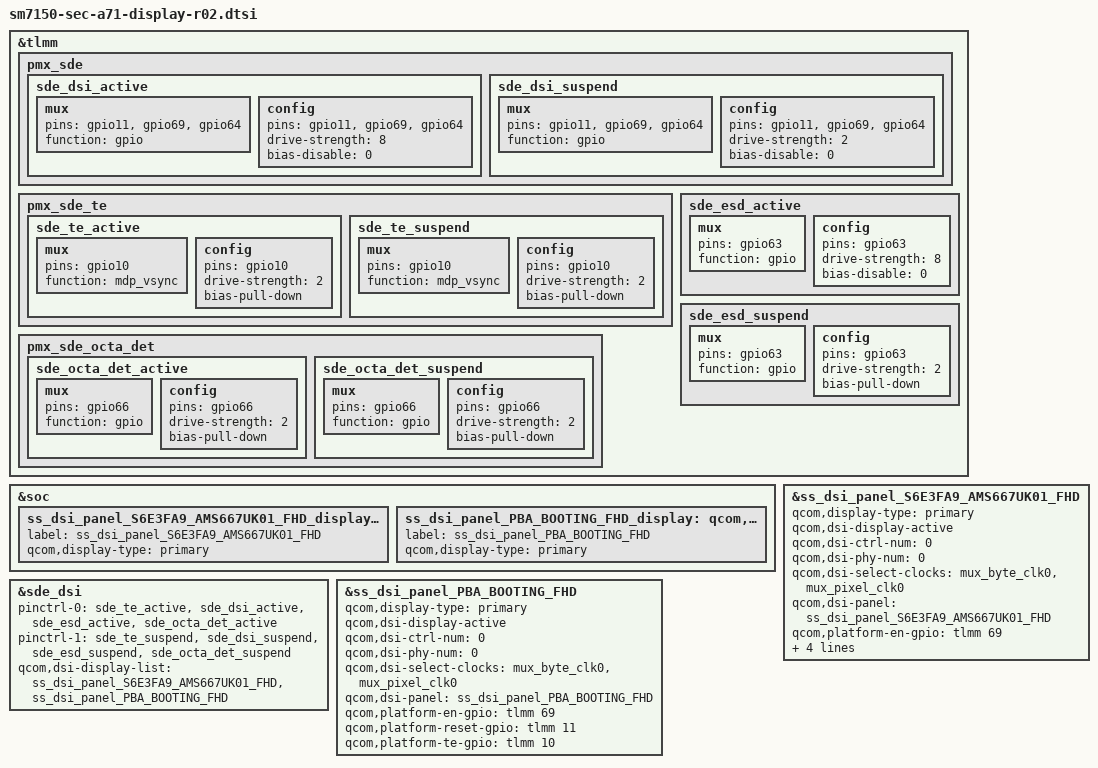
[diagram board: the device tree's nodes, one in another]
/* Copyright (c) 2016-2019, The Linux Foundation. All rights reserved.
 *
 * This program is free software; you can redistribute it and/or modify
 * it under the terms of the GNU General Public License version 2 and
 * only version 2 as published by the Free Software Foundation.
 *
 * This program is distributed in the hope that it will be useful,
 * but WITHOUT ANY WARRANTY; without even the implied warranty of
 * MERCHANTABILITY or FITNESS FOR A PARTICULAR PURPOSE.  See the
 * GNU General Public License for more details.
 */

#include "../../../../../../drivers/gpu/drm/msm/samsung/S6E3FA9_AMS667UK01/dsi_panel_S6E3FA9_AMS667UK01_fhd_octa_cmd.dtsi"
#include "../../../../../../drivers/gpu/drm/msm/samsung/PBA_BOOTING/dsi_panel_PBA_BOOTING_fhd_video.dtsi"

&tlmm {
	pmx_sde: pmx_sde {
		sde_dsi_active: sde_dsi_active {
			mux {
				pins = "gpio11","gpio69", "gpio64";
				function = "gpio";
			};

			config {
				pins = "gpio11","gpio69", "gpio64";
				drive-strength = <8>;   /* 8 mA */
				bias-disable = <0>;   /* no pull */
			};
		};
		sde_dsi_suspend: sde_dsi_suspend {
			mux {
				pins = "gpio11","gpio69", "gpio64";
				function = "gpio";
			};

			config {
				pins = "gpio11","gpio69", "gpio64";
				drive-strength = <2>;   /* 2 mA */
				bias-disable = <0>;   /* no pull */
			};
		};
	};

	pmx_sde_te {
		sde_te_active: sde_te_active {
			mux {
				pins = "gpio10";
				function = "mdp_vsync";
			};

			config {
				pins = "gpio10";
				drive-strength = <2>;   /* 2 mA */
				bias-pull-down;         /* PULL DOWN */
			};
		};

		sde_te_suspend: sde_te_suspend {
			mux {
				pins = "gpio10";
				function = "mdp_vsync";
			};

			config {
				pins = "gpio10";
				drive-strength = <2>;   /* 2 mA */
				bias-pull-down;         /* PULL DOWN */
			};
		};
	};

	pmx_sde_octa_det {
		sde_octa_det_active: sde_octa_det_active {	
			mux {
				pins = "gpio66";
				function = "gpio";
			};

			config {
				pins = "gpio66";
				drive-strength = <2>;   /* 2 mA */
				bias-pull-down;         /* PULL DOWN */
			};
		};

		sde_octa_det_suspend: sde_octa_det_suspend {
			mux {
				pins = "gpio66";
				function = "gpio";
			};

			config {
				pins = "gpio66";
				drive-strength = <2>;   /* 2 mA */
				bias-pull-down;         /* PULL DOWN */
			};
		};
	};
	
		sde_esd_active: sde_esd_active {  /*EL_ON1_DET gpio*/
			mux {
				pins = "gpio63";
				function = "gpio";
			};

			config {
				pins = "gpio63";
				drive-strength = <8>;   /* 8 mA */
				bias-disable = <0>;   /* no pull */
			};
		};
		sde_esd_suspend: sde_esd_suspend {
			mux {
				pins = "gpio63";
				function = "gpio";
			};

			config {
				pins = "gpio63";
				drive-strength = <2>;   /* 2 mA */
				bias-pull-down;         /* PULL DOWN */
			};
		};
};

&soc {
	ss_dsi_panel_S6E3FA9_AMS667UK01_FHD_display: qcom,dsi-display@0 {
		label = "ss_dsi_panel_S6E3FA9_AMS667UK01_FHD";
		qcom,display-type = "primary";
	};

	/* PBA */
	ss_dsi_panel_PBA_BOOTING_FHD_display: qcom,dsi-display@1 {
		label = "ss_dsi_panel_PBA_BOOTING_FHD";
		qcom,display-type = "primary";
	};
};

&sde_dsi {
	pinctrl-names = "panel_active", "panel_suspend";
	pinctrl-0 = <&sde_te_active &sde_dsi_active &sde_esd_active &sde_octa_det_active>;
	pinctrl-1 = <&sde_te_suspend &sde_dsi_suspend &sde_esd_suspend &sde_octa_det_suspend>;

	qcom,dsi-display-list =
		<&ss_dsi_panel_S6E3FA9_AMS667UK01_FHD
		&ss_dsi_panel_PBA_BOOTING_FHD>;
};

&ss_dsi_panel_S6E3FA9_AMS667UK01_FHD {
	qcom,display-type = "primary";
	qcom,dsi-display-active;

	qcom,dsi-ctrl-num = <0>;
	qcom,dsi-phy-num = <0>;
	qcom,dsi-select-clocks = "mux_byte_clk0", "mux_pixel_clk0";

	qcom,dsi-panel = <&ss_dsi_panel_S6E3FA9_AMS667UK01_FHD>;

	qcom,platform-en-gpio = <&tlmm 69 0>;		/* LCD_EN_3P0 */
	qcom,platform-reset-gpio = <&tlmm 11 0>;    /* OCTA_RST_N */
	qcom,platform-te-gpio = <&tlmm 10 0>;       /* DISP_TE	  */

	samsung,ub-con-det = <&tlmm 66 0>; // OCTA_CON_DET
	samsung,support-optical-fingerprint;
};

&ss_dsi_panel_PBA_BOOTING_FHD {
	qcom,display-type = "primary";
	qcom,dsi-display-active;

	qcom,dsi-ctrl-num = <0>;
	qcom,dsi-phy-num = <0>;
	qcom,dsi-select-clocks = "mux_byte_clk0", "mux_pixel_clk0";

	qcom,dsi-panel = <&ss_dsi_panel_PBA_BOOTING_FHD>;

	qcom,platform-en-gpio = <&tlmm 69 0>;
	qcom,platform-reset-gpio = <&tlmm 11 0>;
	qcom,platform-te-gpio = <&tlmm 10 0>;
};
